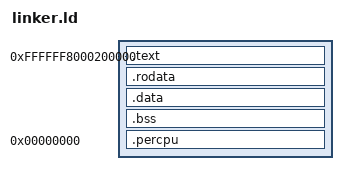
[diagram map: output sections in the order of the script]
ENTRY(arch_entry)
BASE_ADDRESS = 0xffffff8000200000;
CPU_NUM = 4;

SECTIONS
{
    . = BASE_ADDRESS;
    skernel = .;

    stext = .;
    .text : {
        KEEP(*(.text.header))
        *(.text.entry)
        *(.text.entry32)
        *(.text.entry64)
        *(.text .text.*)
    }

    . = ALIGN(4K);
    etext = .;
    srodata = .;
    .rodata : {
        *(.rodata .rodata.*)
        *(.srodata .srodata.*)
    }

    . = ALIGN(4K);
    erodata = .;
    sdata = .;
    .data : {
        *(.data.entry_page_table)
        *(.data .data.*)
        *(.sdata .sdata.*)
    }

    . = ALIGN(4K);
    edata = .;
    .bss : {
        *(.bss.stack)
        sbss = .;
        *(.bss .bss.*)
        *(.sbss .sbss.*)
    }

    . = ALIGN(4K);
    _percpu_start = .;
    _percpu_end = _percpu_start + SIZEOF(.percpu);
    .percpu 0x0 (NOLOAD) : AT(_percpu_start) {
        _percpu_load_start = .;
        *(.percpu .percpu.*)
        _percpu_load_end = .;
        . = _percpu_load_start + ALIGN(64) * CPU_NUM;
    }
    . = _percpu_end;

    . = ALIGN(4K);
    ebss = .;
    ekernel = .;

    /DISCARD/ : {
        *(.eh_frame)
    }
    . = ALIGN(4K);
    __core_end = .;
}

__hv_end = __core_end + HV_EXTENDED_SIZE;
